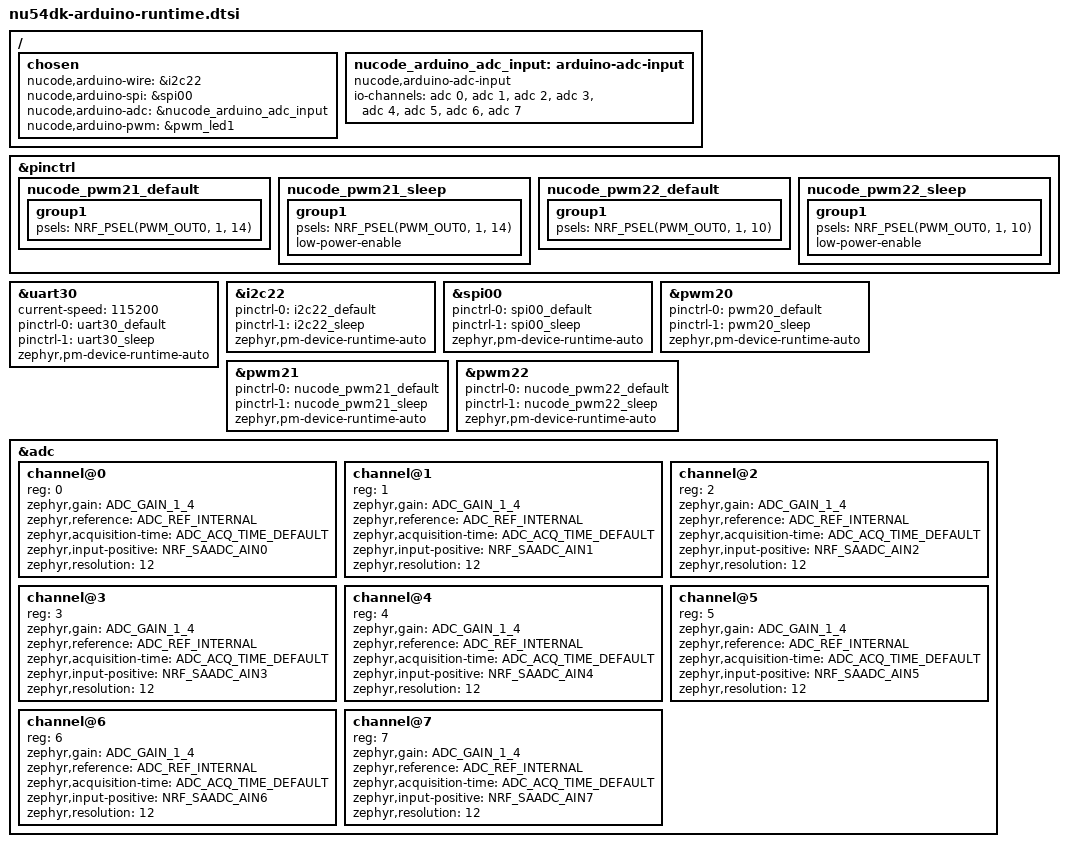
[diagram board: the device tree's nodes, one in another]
/**
 * @file nu54dk-arduino-runtime.dtsi
 * @brief NU54DK Arduino 동적 주변장치와 여덟 SAADC 입력을 활성화합니다.
 *
 * SPDX-License-Identifier: MIT
 */

#include <zephyr/dt-bindings/adc/adc.h>
#include <zephyr/dt-bindings/adc/nrf-saadc.h>
#include <zephyr/dt-bindings/pinctrl/nrf-pinctrl.h>

/ {
	chosen {
		nucode,arduino-wire = &i2c22;
		nucode,arduino-spi = &spi00;
		nucode,arduino-adc = &nucode_arduino_adc_input;
		nucode,arduino-pwm = &pwm_led1;
	};

	nucode_arduino_adc_input: arduino-adc-input {
		compatible = "nucode,arduino-adc-input";
		io-channels = <&adc 0>, <&adc 1>, <&adc 2>, <&adc 3>,
			<&adc 4>, <&adc 5>, <&adc 6>, <&adc 7>;
	};
};

&pinctrl {
	/** @brief PWM21이 runtime route를 설치하기 전 사용하는 안전한 초기 상태입니다. */
	nucode_pwm21_default: nucode_pwm21_default {
		group1 { psels = <NRF_PSEL(PWM_OUT0, 1, 14)>; };
	};
	nucode_pwm21_sleep: nucode_pwm21_sleep {
		group1 {
			psels = <NRF_PSEL(PWM_OUT0, 1, 14)>;
			low-power-enable;
		};
	};

	/** @brief PWM22가 runtime route를 설치하기 전 사용하는 안전한 초기 상태입니다. */
	nucode_pwm22_default: nucode_pwm22_default {
		group1 { psels = <NRF_PSEL(PWM_OUT0, 1, 10)>; };
	};
	nucode_pwm22_sleep: nucode_pwm22_sleep {
		group1 {
			psels = <NRF_PSEL(PWM_OUT0, 1, 10)>;
			low-power-enable;
		};
	};
};

&uart30 {
	status = "okay";
	current-speed = <115200>;
	pinctrl-0 = <&uart30_default>;
	pinctrl-1 = <&uart30_sleep>;
	pinctrl-names = "default", "sleep";
	zephyr,pm-device-runtime-auto;
};

&i2c22 {
	status = "okay";
	pinctrl-0 = <&i2c22_default>;
	pinctrl-1 = <&i2c22_sleep>;
	pinctrl-names = "default", "sleep";
	zephyr,pm-device-runtime-auto;
};

&spi00 {
	status = "okay";
	pinctrl-0 = <&spi00_default>;
	pinctrl-1 = <&spi00_sleep>;
	pinctrl-names = "default", "sleep";
	zephyr,pm-device-runtime-auto;
};

&pwm20 {
	status = "okay";
	pinctrl-0 = <&pwm20_default>;
	pinctrl-1 = <&pwm20_sleep>;
	pinctrl-names = "default", "sleep";
	zephyr,pm-device-runtime-auto;
};

&pwm21 {
	status = "okay";
	pinctrl-0 = <&nucode_pwm21_default>;
	pinctrl-1 = <&nucode_pwm21_sleep>;
	pinctrl-names = "default", "sleep";
	zephyr,pm-device-runtime-auto;
};

&pwm22 {
	status = "okay";
	pinctrl-0 = <&nucode_pwm22_default>;
	pinctrl-1 = <&nucode_pwm22_sleep>;
	pinctrl-names = "default", "sleep";
	zephyr,pm-device-runtime-auto;
};

&adc {
	#address-cells = <1>;
	#size-cells = <0>;
	status = "okay";

	channel@0 {
		reg = <0>;
		zephyr,gain = "ADC_GAIN_1_4";
		zephyr,reference = "ADC_REF_INTERNAL";
		zephyr,acquisition-time = <ADC_ACQ_TIME_DEFAULT>;
		zephyr,input-positive = <NRF_SAADC_AIN0>;
		zephyr,resolution = <12>;
	};
	channel@1 {
		reg = <1>;
		zephyr,gain = "ADC_GAIN_1_4";
		zephyr,reference = "ADC_REF_INTERNAL";
		zephyr,acquisition-time = <ADC_ACQ_TIME_DEFAULT>;
		zephyr,input-positive = <NRF_SAADC_AIN1>;
		zephyr,resolution = <12>;
	};
	channel@2 {
		reg = <2>;
		zephyr,gain = "ADC_GAIN_1_4";
		zephyr,reference = "ADC_REF_INTERNAL";
		zephyr,acquisition-time = <ADC_ACQ_TIME_DEFAULT>;
		zephyr,input-positive = <NRF_SAADC_AIN2>;
		zephyr,resolution = <12>;
	};
	channel@3 {
		reg = <3>;
		zephyr,gain = "ADC_GAIN_1_4";
		zephyr,reference = "ADC_REF_INTERNAL";
		zephyr,acquisition-time = <ADC_ACQ_TIME_DEFAULT>;
		zephyr,input-positive = <NRF_SAADC_AIN3>;
		zephyr,resolution = <12>;
	};
	channel@4 {
		reg = <4>;
		zephyr,gain = "ADC_GAIN_1_4";
		zephyr,reference = "ADC_REF_INTERNAL";
		zephyr,acquisition-time = <ADC_ACQ_TIME_DEFAULT>;
		zephyr,input-positive = <NRF_SAADC_AIN4>;
		zephyr,resolution = <12>;
	};
	channel@5 {
		reg = <5>;
		zephyr,gain = "ADC_GAIN_1_4";
		zephyr,reference = "ADC_REF_INTERNAL";
		zephyr,acquisition-time = <ADC_ACQ_TIME_DEFAULT>;
		zephyr,input-positive = <NRF_SAADC_AIN5>;
		zephyr,resolution = <12>;
	};
	channel@6 {
		reg = <6>;
		zephyr,gain = "ADC_GAIN_1_4";
		zephyr,reference = "ADC_REF_INTERNAL";
		zephyr,acquisition-time = <ADC_ACQ_TIME_DEFAULT>;
		zephyr,input-positive = <NRF_SAADC_AIN6>;
		zephyr,resolution = <12>;
	};
	channel@7 {
		reg = <7>;
		zephyr,gain = "ADC_GAIN_1_4";
		zephyr,reference = "ADC_REF_INTERNAL";
		zephyr,acquisition-time = <ADC_ACQ_TIME_DEFAULT>;
		zephyr,input-positive = <NRF_SAADC_AIN7>;
		zephyr,resolution = <12>;
	};
};
